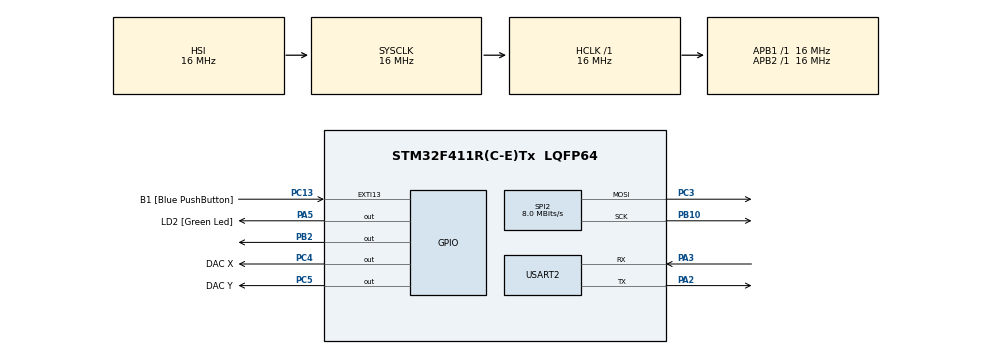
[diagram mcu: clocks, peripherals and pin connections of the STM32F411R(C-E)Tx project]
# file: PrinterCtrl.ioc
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Mcu.Family=STM32F4
PC3.Mode=TX_Only_Simplex_Unidirect_Master
PC15-OSC32_OUT.Mode=LSE-External-Oscillator
PA2.GPIO_PuPd=GPIO_PULLUP
RCC.CortexFreq_Value=16000000
PC13-ANTI_TAMP.GPIO_PuPd=GPIO_NOPULL
SPI2.VirtualType=VM_MASTER
PC4.PinState=GPIO_PIN_SET
PB10.Mode=TX_Only_Simplex_Unidirect_Master
PC13-ANTI_TAMP.GPIO_Label=B1 [Blue PushButton]
PA3.GPIO_PuPd=GPIO_PULLUP
PH1\ -\ OSC_OUT.Mode=HSE-External-Clock-Source
PA2.GPIO_Speed=GPIO_SPEED_FREQ_VERY_HIGH
PC4.Signal=GPIO_Output
PC14-OSC32_IN.Signal=RCC_OSC32_IN
PA3.GPIO_Speed=GPIO_SPEED_FREQ_VERY_HIGH
NVIC.USART2_IRQn=true\:0\:0\:false\:false\:true\:true\:true
ProjectManager.StackSize=0x400
PA3.Mode=Asynchronous
PA13.Signal=SYS_JTMS-SWDIO
PH0\ -\ OSC_IN.Mode=HSE-External-Clock-Source
PH0\ -\ OSC_IN.Signal=RCC_OSC_IN
ProjectManager.TargetToolchain=Makefile
PA3.GPIO_Mode=GPIO_MODE_AF_PP
RCC.HCLKFreq_Value=16000000
RCC.APB2TimFreq_Value=16000000
PC3.Signal=SPI2_MOSI
PC15-OSC32_OUT.Signal=RCC_OSC32_OUT
RCC.AHBFreq_Value=16000000
SPI2.BaudRatePrescaler=SPI_BAUDRATEPRESCALER_2
PB10.Signal=SPI2_SCK
PA5.Signal=GPIO_Output
RCC.HSE_VALUE=8000000
PH1\ -\ OSC_OUT.Signal=RCC_OSC_OUT
PB2.Signal=GPIO_Output
board=NUCLEO-F411RE
PC13-ANTI_TAMP.Signal=GPXTI13
RCC.VCOOutputFreq_Value=336000000
RCC.APB2Freq_Value=16000000
PC14-OSC32_IN.Mode=LSE-External-Oscillator
PC4.GPIO_Label=DAC X
PA14.Mode=Serial_Wire
SPI2.CalculateBaudRate=8.0 MBits/s
NVIC.SPI2_IRQn=true\:0\:0\:false\:false\:true\:true\:true
PA13.Mode=Serial_Wire
Mcu.Name=STM32F411R(C-E)Tx
PB2.PinState=GPIO_PIN_SET
PA2.Signal=USART2_TX
RCC.FLatency-AdvancedSettings=FLASH_LATENCY_0
RCC.48MHZClocksFreq_Value=84000000
PB3.Signal=SYS_JTDO-SWO
RCC.SYSCLKFreq_VALUE=16000000
Mcu.Package=LQFP64
SPI2.Mode=SPI_MODE_MASTER
PC5.PinState=GPIO_PIN_SET
PA5.GPIO_Label=LD2 [Green Led]
PC5.GPIO_Label=DAC Y
USART2.VirtualMode=VM_ASYNC
PC13-ANTI_TAMP.GPIO_ModeDefaultEXTI=GPIO_MODE_IT_RISING
PA14.Signal=SYS_JTCK-SWCLK
ProjectManager.HeapSize=0x200
SPI2.CLKPhase=SPI_PHASE_1EDGE
RCC.HSI_VALUE=16000000
RCC.PLLP=RCC_PLLP_DIV4
NVIC.PriorityGroup=NVIC_PRIORITYGROUP_0
RCC.PLLN=336
RCC.APB1TimFreq_Value=16000000
PA2.Mode=Asynchronous
SPI2.DataSize=SPI_DATASIZE_8BIT
SPI2.Direction=SPI_DIRECTION_2LINES
PC5.Signal=GPIO_Output
RCC.APB1Freq_Value=16000000
PA3.Signal=USART2_RX
PA2.GPIO_Mode=GPIO_MODE_AF_PP

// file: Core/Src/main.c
/* USER CODE BEGIN Header */
/**
 ******************************************************************************
 * @file           : main.c
 * @brief          : Main program body
 ******************************************************************************
 ** This notice applies to any and all portions of this file
 * that are not between comment pairs USER CODE BEGIN and
 * USER CODE END. Other portions of this file, whether
 * inserted by the user or by software development tools
 * are owned by their respective copyright owners.
 *
 * COPYRIGHT(c) 2019 STMicroelectronics
 *
 * Redistribution and use in source and binary forms, with or without modification,
 * are permitted provided that the following conditions are met:
 *   1. Redistributions of source code must retain the above copyright notice,
 *      this list of conditions and the following disclaimer.
 *   2. Redistributions in binary form must reproduce the above copyright notice,
 *      this list of conditions and the following disclaimer in the documentation
 *      and/or other materials provided with the distribution.
 *   3. Neither the name of STMicroelectronics nor the names of its contributors
 *      may be used to endorse or promote products derived from this software
 *      without specific prior written permission.
 *
 * THIS SOFTWARE IS PROVIDED BY THE COPYRIGHT HOLDERS AND CONTRIBUTORS "AS IS"
 * AND ANY EXPRESS OR IMPLIED WARRANTIES, INCLUDING, BUT NOT LIMITED TO, THE
 * IMPLIED WARRANTIES OF MERCHANTABILITY AND FITNESS FOR A PARTICULAR PURPOSE ARE
 * DISCLAIMED. IN NO EVENT SHALL THE COPYRIGHT HOLDER OR CONTRIBUTORS BE LIABLE
 * FOR ANY DIRECT, INDIRECT, INCIDENTAL, SPECIAL, EXEMPLARY, OR CONSEQUENTIAL
 * DAMAGES (INCLUDING, BUT NOT LIMITED TO, PROCUREMENT OF SUBSTITUTE GOODS OR
 * SERVICES; LOSS OF USE, DATA, OR PROFITS; OR BUSINESS INTERRUPTION) HOWEVER
 * CAUSED AND ON ANY THEORY OF LIABILITY, WHETHER IN CONTRACT, STRICT LIABILITY,
 * OR TORT (INCLUDING NEGLIGENCE OR OTHERWISE) ARISING IN ANY WAY OUT OF THE USE
 * OF THIS SOFTWARE, EVEN IF ADVISED OF THE POSSIBILITY OF SUCH DAMAGE.
 *
 ******************************************************************************
 */
#define TEST
/* USER CODE END Header */
#include "main.h"
#include "gpio.h"
#include "spi.h"
#include "usart.h"

/* USER CODE BEGIN Includes */
#ifdef TEST
#include "Test/dac_test.h"
#include "Test/laser_test.h"
#include "Test/usart_test.h"
#endif
/* USER CODE END Includes */

void SystemClock_Config(void);

int main(void)
{

    /* MCU Configuration--------------------------------------------------------*/

    /* Reset of all peripherals, Initializes the Flash interface and the Systick. */
    HAL_Init();

    /* Configure the system clock */
    SystemClock_Config();

    /* Initialize all configured peripherals */
    MX_GPIO_Init();
    MX_USART2_UART_Init();
    MX_SPI2_Init();
    /* USER CODE BEGIN 2 */
#ifndef TEST
    run_init();
#endif
    /* USER CODE END 2 */

    /* Infinite loop */
    while(1)
    {

        /* USER CODE BEGIN 3 */
#ifndef TEST
        run_loop();
#endif

        dac_test();
    }
    /* USER CODE END 3 */
}

void SystemClock_Config(void)
{
    RCC_OscInitTypeDef RCC_OscInitStruct = {0};
    RCC_ClkInitTypeDef RCC_ClkInitStruct = {0};

    /** Configure the main internal regulator output voltage
  */
    __HAL_RCC_PWR_CLK_ENABLE();
    __HAL_PWR_VOLTAGESCALING_CONFIG(PWR_REGULATOR_VOLTAGE_SCALE1);
    /** Initializes the RCC Oscillators according to the specified parameters
  * in the RCC_OscInitTypeDef structure.
  */
    RCC_OscInitStruct.OscillatorType = RCC_OSCILLATORTYPE_HSI;
    RCC_OscInitStruct.HSIState = RCC_HSI_ON;
    RCC_OscInitStruct.HSICalibrationValue = RCC_HSICALIBRATION_DEFAULT;
    RCC_OscInitStruct.PLL.PLLState = RCC_PLL_NONE;
    if(HAL_RCC_OscConfig(&RCC_OscInitStruct) != HAL_OK)
    {
        Error_Handler();
    }
    /** Initializes the CPU, AHB and APB buses clocks
  */
    RCC_ClkInitStruct.ClockType =
            RCC_CLOCKTYPE_HCLK | RCC_CLOCKTYPE_SYSCLK | RCC_CLOCKTYPE_PCLK1 | RCC_CLOCKTYPE_PCLK2;
    RCC_ClkInitStruct.SYSCLKSource = RCC_SYSCLKSOURCE_HSI;
    RCC_ClkInitStruct.AHBCLKDivider = RCC_SYSCLK_DIV1;
    RCC_ClkInitStruct.APB1CLKDivider = RCC_HCLK_DIV1;
    RCC_ClkInitStruct.APB2CLKDivider = RCC_HCLK_DIV1;

    if(HAL_RCC_ClockConfig(&RCC_ClkInitStruct, FLASH_LATENCY_0) != HAL_OK)
    {
        Error_Handler();
    }
}

void Error_Handler(void)
{
}

/************************ (C) COPYRIGHT STMicroelectronics *****END OF FILE****/
